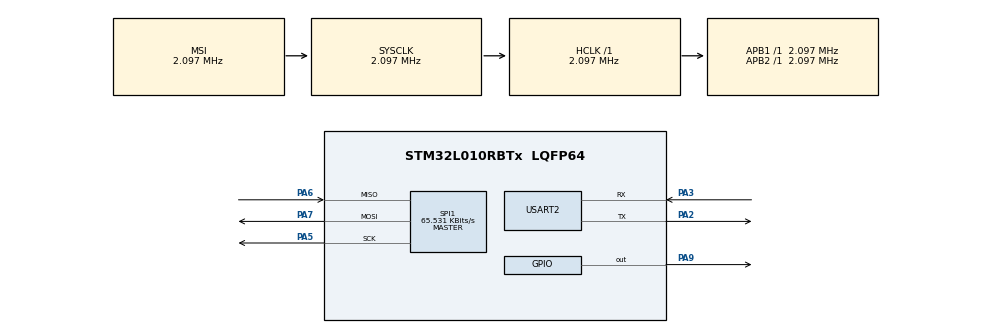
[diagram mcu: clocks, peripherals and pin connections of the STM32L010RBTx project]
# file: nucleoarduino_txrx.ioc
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Mcu.Family=STM32L0
Mcu.Name=STM32L010RBTx
Mcu.Package=LQFP64
PA13.GPIO_Label=TMS
PA13.Mode=Serial_Wire
PA13.Signal=SYS_SWDIO
PA14.GPIO_Label=TCK
PA14.Mode=Serial_Wire
PA14.Signal=SYS_SWCLK
PA2.Mode=Asynchronous
PA2.Signal=USART2_TX
PA3.Mode=Asynchronous
PA3.Signal=USART2_RX
PA4.Signal=SPI1_NSS
PA5.Mode=Full_Duplex_Master
PA5.Signal=SPI1_SCK
PA6.Mode=Full_Duplex_Master
PA6.Signal=SPI1_MISO
PA7.Mode=Full_Duplex_Master
PA7.Signal=SPI1_MOSI
PA9.Signal=GPIO_Output
PC14-OSC32_IN.Mode=LSE-External-Oscillator
PC14-OSC32_IN.Signal=RCC_OSC32_IN
PC15-OSC32_OUT.Mode=LSE-External-Oscillator
PC15-OSC32_OUT.Signal=RCC_OSC32_OUT
PH0-OSC_IN.GPIO_Label=MCO
PH0-OSC_IN.Mode=HSE-External-Clock-Source
PH0-OSC_IN.Signal=RCC_OSC_IN
ProjectManager.HeapSize=0x200
ProjectManager.StackSize=0x400
ProjectManager.TargetToolchain=STM32CubeIDE
RCC.AHBFreq_Value=2097000
RCC.APB1Freq_Value=2097000
RCC.APB1TimFreq_Value=2097000
RCC.APB2Freq_Value=2097000
RCC.APB2TimFreq_Value=2097000
RCC.HSE_VALUE=8000000
RCC.HSI16_VALUE=16000000
RCC.HSI48_VALUE=48000000
RCC.HSI_VALUE=16000000
RCC.MSI_VALUE=2097000
RCC.SYSCLKFreq_VALUE=2097000
RCC.VCOOutputFreq_Value=48000000
SPI1.BaudRatePrescaler=SPI_BAUDRATEPRESCALER_32
SPI1.CalculateBaudRate=65.531 KBits/s
SPI1.Direction=SPI_DIRECTION_2LINES
SPI1.Mode=SPI_MODE_MASTER
SPI1.VirtualType=VM_MASTER
USART2.VirtualMode-Asynchronous=VM_ASYNC
board=NUCLEO-L010RB

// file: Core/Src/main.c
/* USER CODE BEGIN Header */
/**
  ******************************************************************************
  * @file           : main.c
  * @brief          : Main program body
  ******************************************************************************
  * @attention
  *
  * Copyright (c) 2026 STMicroelectronics.
  * All rights reserved.
  *
  * This software is licensed under terms that can be found in the LICENSE file
  * in the root directory of this software component.
  * If no LICENSE file comes with this software, it is provided AS-IS.
  *
  ******************************************************************************
  */
/* USER CODE END Header */
#include "main.h"

SPI_HandleTypeDef hspi1;

UART_HandleTypeDef huart2;

void SystemClock_Config(void);
static void MX_GPIO_Init(void);
static void MX_SPI1_Init(void);
static void MX_USART2_UART_Init(void);

/* USER CODE BEGIN 0 */
uint8_t masterTxBuffer[5] = "blue"; // Padding with spaces to match length
uint8_t masterRxBuffer[5] = {0};
/* USER CODE END 0 */

int main(void)
{

  /* MCU Configuration--------------------------------------------------------*/

  /* Reset of all peripherals, Initializes the Flash interface and the Systick. */
  HAL_Init();

  /* Configure the system clock */
  SystemClock_Config();

  /* Initialize all configured peripherals */
  MX_GPIO_Init();
  MX_SPI1_Init();
  MX_USART2_UART_Init();

  /* Infinite loop */
  /* USER CODE BEGIN WHILE */
  while (1)
  {
	  for(int i = 0; i < 5; i++)
	  {
	            masterRxBuffer[i] = 0;
	  }
	            HAL_SPI_TransmitReceive(&hspi1, masterTxBuffer, masterRxBuffer, 5, 1000);
	            HAL_UART_Transmit(&huart2, masterRxBuffer, 4, 100);
	            HAL_UART_Transmit(&huart2, (uint8_t*)"\r\n", 2, 10);
	            HAL_Delay(2000);
    /* USER CODE END WHILE */

    /* USER CODE BEGIN 3 */
	    }
    /* USER CODE END WHILE */

    /* USER CODE BEGIN 3 */
  }
  /* USER CODE END 3 */

void SystemClock_Config(void)
{
  RCC_OscInitTypeDef RCC_OscInitStruct = {0};
  RCC_ClkInitTypeDef RCC_ClkInitStruct = {0};
  RCC_PeriphCLKInitTypeDef PeriphClkInit = {0};

  /** Configure the main internal regulator output voltage
  */
  __HAL_PWR_VOLTAGESCALING_CONFIG(PWR_REGULATOR_VOLTAGE_SCALE1);

  /** Initializes the RCC Oscillators according to the specified parameters
  * in the RCC_OscInitTypeDef structure.
  */
  RCC_OscInitStruct.OscillatorType = RCC_OSCILLATORTYPE_MSI;
  RCC_OscInitStruct.MSIState = RCC_MSI_ON;
  RCC_OscInitStruct.MSICalibrationValue = 0;
  RCC_OscInitStruct.MSIClockRange = RCC_MSIRANGE_5;
  RCC_OscInitStruct.PLL.PLLState = RCC_PLL_NONE;
  if (HAL_RCC_OscConfig(&RCC_OscInitStruct) != HAL_OK)
  {
    Error_Handler();
  }

  /** Initializes the CPU, AHB and APB buses clocks
  */
  RCC_ClkInitStruct.ClockType = RCC_CLOCKTYPE_HCLK|RCC_CLOCKTYPE_SYSCLK
                              |RCC_CLOCKTYPE_PCLK1|RCC_CLOCKTYPE_PCLK2;
  RCC_ClkInitStruct.SYSCLKSource = RCC_SYSCLKSOURCE_MSI;
  RCC_ClkInitStruct.AHBCLKDivider = RCC_SYSCLK_DIV1;
  RCC_ClkInitStruct.APB1CLKDivider = RCC_HCLK_DIV1;
  RCC_ClkInitStruct.APB2CLKDivider = RCC_HCLK_DIV1;

  if (HAL_RCC_ClockConfig(&RCC_ClkInitStruct, FLASH_LATENCY_0) != HAL_OK)
  {
    Error_Handler();
  }
  PeriphClkInit.PeriphClockSelection = RCC_PERIPHCLK_USART2;
  PeriphClkInit.Usart2ClockSelection = RCC_USART2CLKSOURCE_PCLK1;
  if (HAL_RCCEx_PeriphCLKConfig(&PeriphClkInit) != HAL_OK)
  {
    Error_Handler();
  }
}

static void MX_SPI1_Init(void)
{

  /* SPI1 parameter configuration*/
  hspi1.Instance = SPI1;
  hspi1.Init.Mode = SPI_MODE_MASTER;
  hspi1.Init.Direction = SPI_DIRECTION_2LINES;
  hspi1.Init.DataSize = SPI_DATASIZE_8BIT;
  hspi1.Init.CLKPolarity = SPI_POLARITY_LOW;
  hspi1.Init.CLKPhase = SPI_PHASE_1EDGE;
  hspi1.Init.NSS = SPI_NSS_SOFT;
  hspi1.Init.BaudRatePrescaler = SPI_BAUDRATEPRESCALER_32;
  hspi1.Init.FirstBit = SPI_FIRSTBIT_MSB;
  hspi1.Init.TIMode = SPI_TIMODE_DISABLE;
  hspi1.Init.CRCCalculation = SPI_CRCCALCULATION_DISABLE;
  hspi1.Init.CRCPolynomial = 7;
  if (HAL_SPI_Init(&hspi1) != HAL_OK)
  {
    Error_Handler();
  }

}

static void MX_USART2_UART_Init(void)
{

  huart2.Instance = USART2;
  huart2.Init.BaudRate = 115200;
  huart2.Init.WordLength = UART_WORDLENGTH_8B;
  huart2.Init.StopBits = UART_STOPBITS_1;
  huart2.Init.Parity = UART_PARITY_NONE;
  huart2.Init.Mode = UART_MODE_TX_RX;
  huart2.Init.HwFlowCtl = UART_HWCONTROL_NONE;
  huart2.Init.OverSampling = UART_OVERSAMPLING_16;
  huart2.Init.OneBitSampling = UART_ONE_BIT_SAMPLE_DISABLE;
  huart2.AdvancedInit.AdvFeatureInit = UART_ADVFEATURE_NO_INIT;
  if (HAL_UART_Init(&huart2) != HAL_OK)
  {
    Error_Handler();
  }

}

static void MX_GPIO_Init(void)
{
  GPIO_InitTypeDef GPIO_InitStruct = {0};

  /* GPIO Ports Clock Enable */
  __HAL_RCC_GPIOC_CLK_ENABLE();
  __HAL_RCC_GPIOH_CLK_ENABLE();
  __HAL_RCC_GPIOA_CLK_ENABLE();

  /*Configure GPIO pin Output Level */
  HAL_GPIO_WritePin(GPIOA, GPIO_PIN_9, GPIO_PIN_RESET);

  /*Configure GPIO pin : PA9 */
  GPIO_InitStruct.Pin = GPIO_PIN_9;
  GPIO_InitStruct.Mode = GPIO_MODE_OUTPUT_PP;
  GPIO_InitStruct.Pull = GPIO_NOPULL;
  GPIO_InitStruct.Speed = GPIO_SPEED_FREQ_LOW;
  HAL_GPIO_Init(GPIOA, &GPIO_InitStruct);

}

void Error_Handler(void)
{
  __disable_irq();
  while (1)
  {
  }
}
